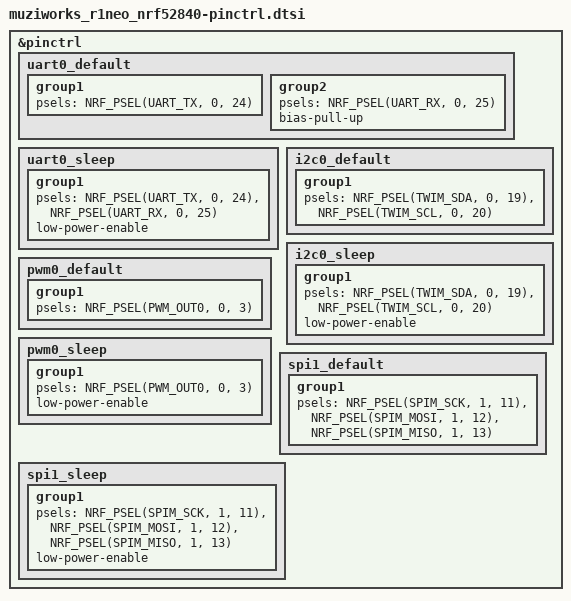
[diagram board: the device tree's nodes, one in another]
/*
 * muzi works R1 Neo - Pin Control
 * Copyright (c) 2026 ZephCore
 * SPDX-License-Identifier: MIT
 */

&pinctrl {
	/* GNSS UART.
	 *
	 * Direction note: the schematic net names UART_GPS_RX (P0.24) and
	 * UART_GPS_TX (P0.25) are labelled from the GPS module's point of
	 * view, so UART_GPS_RX is the module's input and therefore the MCU's
	 * TX, and UART_GPS_TX is the MCU's RX. Arduino MeshCore's variant takes
	 * the net names literally and has them the other way round, which
	 * leaves the MCU listening on the module's own input pin — i.e.
	 * silence, and no fix, ever. The mapping below is the correct one. */
	uart0_default: uart0_default {
		group1 {
			psels = <NRF_PSEL(UART_TX, 0, 24)>;
		};
		group2 {
			psels = <NRF_PSEL(UART_RX, 0, 25)>;
			bias-pull-up;
		};
	};

	uart0_sleep: uart0_sleep {
		group1 {
			psels = <NRF_PSEL(UART_TX, 0, 24)>,
			        <NRF_PSEL(UART_RX, 0, 25)>;
			low-power-enable;
		};
	};

	/* I2C0 - RX8130CE RTC (0x32) + optional Grove-style sensors */
	i2c0_default: i2c0_default {
		group1 {
			psels = <NRF_PSEL(TWIM_SDA, 0, 19)>,
			        <NRF_PSEL(TWIM_SCL, 0, 20)>;
		};
	};

	i2c0_sleep: i2c0_sleep {
		group1 {
			psels = <NRF_PSEL(TWIM_SDA, 0, 19)>,
			        <NRF_PSEL(TWIM_SCL, 0, 20)>;
			low-power-enable;
		};
	};

	/* PWM0 for buzzer */
	pwm0_default: pwm0_default {
		group1 {
			psels = <NRF_PSEL(PWM_OUT0, 0, 3)>;
		};
	};

	pwm0_sleep: pwm0_sleep {
		group1 {
			psels = <NRF_PSEL(PWM_OUT0, 0, 3)>;
			low-power-enable;
		};
	};

	/* SPI1 for SX1262 - CS controlled manually */
	spi1_default: spi1_default {
		group1 {
			psels = <NRF_PSEL(SPIM_SCK, 1, 11)>,
			        <NRF_PSEL(SPIM_MOSI, 1, 12)>,
			        <NRF_PSEL(SPIM_MISO, 1, 13)>;
		};
	};

	spi1_sleep: spi1_sleep {
		group1 {
			psels = <NRF_PSEL(SPIM_SCK, 1, 11)>,
			        <NRF_PSEL(SPIM_MOSI, 1, 12)>,
			        <NRF_PSEL(SPIM_MISO, 1, 13)>;
			low-power-enable;
		};
	};
};
